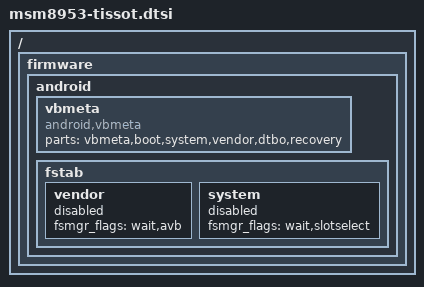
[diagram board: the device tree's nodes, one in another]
/*
 * Copyright (c) 2015-2017, The Linux Foundation. All rights reserved.
 *
 * This program is free software; you can redistribute it and/or modify
 * it under the terms of the GNU General Public License version 2 and
 * only version 2 as published by the Free Software Foundation.
 *
 * This program is distributed in the hope that it will be useful,
 * but WITHOUT ANY WARRANTY; without even the implied warranty of
 * MERCHANTABILITY or FITNESS FOR A PARTICULAR PURPOSE.  See the
 * GNU General Public License for more details.
 */

#include <dt-bindings/clock/msm-clocks-8953.h>
#include <dt-bindings/regulator/qcom,rpm-smd-regulator.h>
#include <dt-bindings/gpio/gpio.h>

/ {
	firmware: firmware {
		android {
			vbmeta {
				compatible = "android,vbmeta";
				parts = "vbmeta,boot,system,vendor,dtbo,recovery";
			};
			fstab {
				vendor {
					fsmgr_flags = "wait,avb";
					status = "disable";
				};
				system {
					fsmgr_flags = "wait,slotselect";
					status = "disable";
				};
			};
		};
	};
};
